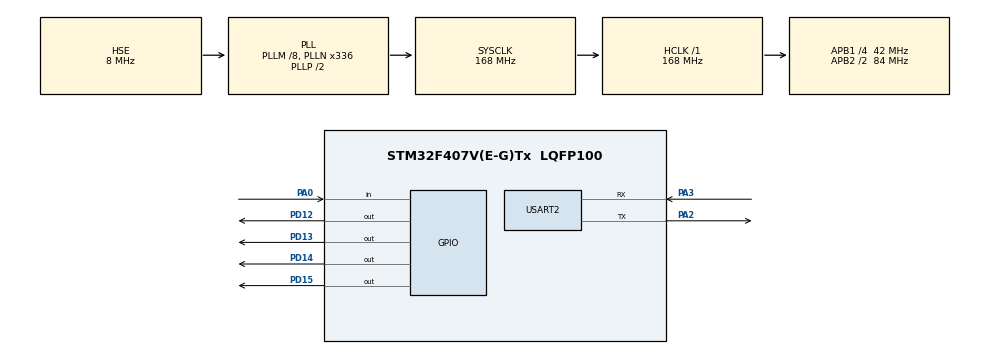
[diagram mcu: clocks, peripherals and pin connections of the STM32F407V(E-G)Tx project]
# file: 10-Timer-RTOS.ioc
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FREERTOS.Tasks01=UART_Task,0,128,UART,Default,NULL,Dynamic,NULL,NULL;LED_Task,0,128,LED,Default,NULL,Dynamic,NULL,NULL
FREERTOS.Timers01=PeriodicTimer,PTCallback01,osTimerPeriodic,Default,NULL,Dynamic,NULL;OnceTimer,OS_Callback,osTimerPeriodic,Default,NULL,Dynamic,NULL
FREERTOS.configUSE_TIMERS=1
Mcu.Family=STM32F4
Mcu.Name=STM32F407V(E-G)Tx
Mcu.Package=LQFP100
NVIC.PriorityGroup=NVIC_PRIORITYGROUP_4
NVIC.TIM6_DAC_IRQn=true\:15\:0\:false\:false\:true\:false\:false\:true\:true
NVIC.TimeBase=TIM6_DAC_IRQn
NVIC.TimeBaseIP=TIM6
PA0-WKUP.Signal=GPIO_Input
PA2.Mode=Asynchronous
PA2.Signal=USART2_TX
PA3.Mode=Asynchronous
PA3.Signal=USART2_RX
PD12.Signal=GPIO_Output
PD13.Signal=GPIO_Output
PD14.Signal=GPIO_Output
PD15.Signal=GPIO_Output
PH0-OSC_IN.Mode=HSE-External-Oscillator
PH0-OSC_IN.Signal=RCC_OSC_IN
PH1-OSC_OUT.Mode=HSE-External-Oscillator
PH1-OSC_OUT.Signal=RCC_OSC_OUT
ProjectManager.HeapSize=0x200
ProjectManager.StackSize=0x400
ProjectManager.TargetToolchain=STM32CubeIDE
RCC.48MHZClocksFreq_Value=48000000
RCC.AHBFreq_Value=168000000
RCC.APB1CLKDivider=RCC_HCLK_DIV4
RCC.APB1Freq_Value=42000000
RCC.APB1TimFreq_Value=84000000
RCC.APB2CLKDivider=RCC_HCLK_DIV2
RCC.APB2Freq_Value=84000000
RCC.APB2TimFreq_Value=168000000
RCC.CortexFreq_Value=168000000
RCC.HCLKFreq_Value=168000000
RCC.HSE_VALUE=8000000
RCC.HSI_VALUE=16000000
RCC.PLLM=8
RCC.PLLN=336
RCC.PLLQ=7
RCC.PLLSourceVirtual=RCC_PLLSOURCE_HSE
RCC.SYSCLKFreq_VALUE=168000000
RCC.SYSCLKSource=RCC_SYSCLKSOURCE_PLLCLK
RCC.VCOOutputFreq_Value=336000000
USART2.VirtualMode=VM_ASYNC
VP_FREERTOS_VS_CMSIS_V1.Mode=CMSIS_V1
VP_SYS_VS_tim6.Mode=TIM6
board=STM32F407G-DISC1

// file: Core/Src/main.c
/* USER CODE BEGIN Header */
/**
  ******************************************************************************
  * @file           : main.c
  * @brief          : Main program body
  ******************************************************************************
  * @attention
  *
  * Copyright (c) 2026 STMicroelectronics.
  * All rights reserved.
  *
  * This software is licensed under terms that can be found in the LICENSE file
  * in the root directory of this software component.
  * If no LICENSE file comes with this software, it is provided AS-IS.
  *
  ******************************************************************************
  */
/* USER CODE END Header */
#include "main.h"
#include "cmsis_os.h"

UART_HandleTypeDef huart2;

osThreadId UART_TaskHandle;
osThreadId LED_TaskHandle;
osTimerId PeriodicTimerHandle;
osTimerId OnceTimerHandle;

void SystemClock_Config(void);
static void MX_GPIO_Init(void);
static void MX_USART2_UART_Init(void);
void UART(void const * argument);
void LED(void const * argument);
void PTCallback01(void const * argument);
void OS_Callback(void const * argument);

int main(void)
{

  /* MCU Configuration--------------------------------------------------------*/

  /* Reset of all peripherals, Initializes the Flash interface and the Systick. */
  HAL_Init();

  /* Configure the system clock */
  SystemClock_Config();

  /* Initialize all configured peripherals */
  MX_GPIO_Init();
  MX_USART2_UART_Init();

  /* Create the timer(s) */
  /* definition and creation of PeriodicTimer */
  osTimerDef(PeriodicTimer, PTCallback01);
  PeriodicTimerHandle = osTimerCreate(osTimer(PeriodicTimer), osTimerPeriodic, NULL);

  /* definition and creation of OnceTimer */
  osTimerDef(OnceTimer, OS_Callback);
  OnceTimerHandle = osTimerCreate(osTimer(OnceTimer), osTimerPeriodic, NULL);

  /* Create the thread(s) */
  /* definition and creation of UART_Task */
  osThreadDef(UART_Task, UART, osPriorityNormal, 0, 128);
  UART_TaskHandle = osThreadCreate(osThread(UART_Task), NULL);

  /* definition and creation of LED_Task */
  osThreadDef(LED_Task, LED, osPriorityNormal, 0, 128);
  LED_TaskHandle = osThreadCreate(osThread(LED_Task), NULL);

  /* Start scheduler */
  osKernelStart();

  /* We should never get here as control is now taken by the scheduler */

  /* Infinite loop */
  while (1)
  {

  }
}

void SystemClock_Config(void)
{
  RCC_OscInitTypeDef RCC_OscInitStruct = {0};
  RCC_ClkInitTypeDef RCC_ClkInitStruct = {0};

  /** Configure the main internal regulator output voltage
  */
  __HAL_RCC_PWR_CLK_ENABLE();
  __HAL_PWR_VOLTAGESCALING_CONFIG(PWR_REGULATOR_VOLTAGE_SCALE1);

  /** Initializes the RCC Oscillators according to the specified parameters
  * in the RCC_OscInitTypeDef structure.
  */
  RCC_OscInitStruct.OscillatorType = RCC_OSCILLATORTYPE_HSE;
  RCC_OscInitStruct.HSEState = RCC_HSE_ON;
  RCC_OscInitStruct.PLL.PLLState = RCC_PLL_ON;
  RCC_OscInitStruct.PLL.PLLSource = RCC_PLLSOURCE_HSE;
  RCC_OscInitStruct.PLL.PLLM = 8;
  RCC_OscInitStruct.PLL.PLLN = 336;
  RCC_OscInitStruct.PLL.PLLP = RCC_PLLP_DIV2;
  RCC_OscInitStruct.PLL.PLLQ = 7;
  if (HAL_RCC_OscConfig(&RCC_OscInitStruct) != HAL_OK)
  {
    Error_Handler();
  }

  /** Initializes the CPU, AHB and APB buses clocks
  */
  RCC_ClkInitStruct.ClockType = RCC_CLOCKTYPE_HCLK|RCC_CLOCKTYPE_SYSCLK
                              |RCC_CLOCKTYPE_PCLK1|RCC_CLOCKTYPE_PCLK2;
  RCC_ClkInitStruct.SYSCLKSource = RCC_SYSCLKSOURCE_PLLCLK;
  RCC_ClkInitStruct.AHBCLKDivider = RCC_SYSCLK_DIV1;
  RCC_ClkInitStruct.APB1CLKDivider = RCC_HCLK_DIV4;
  RCC_ClkInitStruct.APB2CLKDivider = RCC_HCLK_DIV2;

  if (HAL_RCC_ClockConfig(&RCC_ClkInitStruct, FLASH_LATENCY_5) != HAL_OK)
  {
    Error_Handler();
  }
}

static void MX_USART2_UART_Init(void)
{

  huart2.Instance = USART2;
  huart2.Init.BaudRate = 115200;
  huart2.Init.WordLength = UART_WORDLENGTH_8B;
  huart2.Init.StopBits = UART_STOPBITS_1;
  huart2.Init.Parity = UART_PARITY_NONE;
  huart2.Init.Mode = UART_MODE_TX_RX;
  huart2.Init.HwFlowCtl = UART_HWCONTROL_NONE;
  huart2.Init.OverSampling = UART_OVERSAMPLING_16;
  if (HAL_UART_Init(&huart2) != HAL_OK)
  {
    Error_Handler();
  }

}

static void MX_GPIO_Init(void)
{
  GPIO_InitTypeDef GPIO_InitStruct = {0};

  /* GPIO Ports Clock Enable */
  __HAL_RCC_GPIOH_CLK_ENABLE();
  __HAL_RCC_GPIOA_CLK_ENABLE();
  __HAL_RCC_GPIOD_CLK_ENABLE();

  /*Configure GPIO pin Output Level */
  HAL_GPIO_WritePin(GPIOD, GPIO_PIN_12|GPIO_PIN_13|GPIO_PIN_14|GPIO_PIN_15, GPIO_PIN_RESET);

  /*Configure GPIO pin : PA0 */
  GPIO_InitStruct.Pin = GPIO_PIN_0;
  GPIO_InitStruct.Mode = GPIO_MODE_INPUT;
  GPIO_InitStruct.Pull = GPIO_NOPULL;
  HAL_GPIO_Init(GPIOA, &GPIO_InitStruct);

  /*Configure GPIO pins : PD12 PD13 PD14 PD15 */
  GPIO_InitStruct.Pin = GPIO_PIN_12|GPIO_PIN_13|GPIO_PIN_14|GPIO_PIN_15;
  GPIO_InitStruct.Mode = GPIO_MODE_OUTPUT_PP;
  GPIO_InitStruct.Pull = GPIO_NOPULL;
  GPIO_InitStruct.Speed = GPIO_SPEED_FREQ_LOW;
  HAL_GPIO_Init(GPIOD, &GPIO_InitStruct);

}

void UART(void const * argument)
{
  /* USER CODE BEGIN 5 */
	osTimerStart(PeriodicTimerHandle, 100);
  /* Infinite loop */
  for(;;)
  {
	uint8_t mssg[] = "LEVI from WALL_MARIYA (UART)\n";
	HAL_UART_Transmit(&huart2, mssg, sizeof(mssg), 100);
    osDelay(1000);
  }
  /* USER CODE END 5 */
}

void LED(void const * argument)
{
  /* USER CODE BEGIN LED */
  /* Infinite loop */
  for(;;)
  {
	  if(HAL_GPIO_ReadPin(GPIOA, GPIO_PIN_0)){
		  HAL_GPIO_WritePin(GPIOD, GPIO_PIN_14, GPIO_PIN_SET);
		  osTimerStart(OnceTimerHandle, 2000);
	  }

    //osDelay(1);
  }
  /* USER CODE END LED */
}

/* PTCallback01 function */
void PTCallback01(void const * argument)
{
  /* USER CODE BEGIN PTCallback01 */
	uint8_t mmsg[] = "EREN YEAGER from WALL_ROSE (Periodic)";
		  HAL_UART_Transmit(&huart2, mmsg, sizeof(mmsg), 100);
  /* USER CODE END PTCallback01 */
}

/* OS_Callback function */
void OS_Callback(void const * argument)
{
  /* USER CODE BEGIN OS_Callback */
	HAL_GPIO_WritePin(GPIOD, GPIO_PIN_14, GPIO_PIN_0);
  /* USER CODE END OS_Callback */
}

void HAL_TIM_PeriodElapsedCallback(TIM_HandleTypeDef *htim)
{
  if (htim->Instance == TIM6)
  {
    HAL_IncTick();
  }
}

void Error_Handler(void)
{
  __disable_irq();
  while (1)
  {
  }
}
